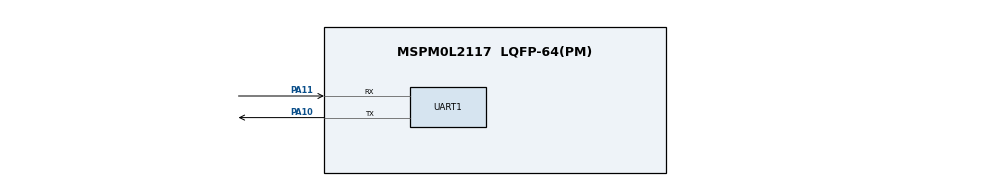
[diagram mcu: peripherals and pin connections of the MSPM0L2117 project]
//@cliArgs --device "MSPM0L211X" --package "LQFP-64(PM)" --part "Default"
//@v2CliArgs --device "MSPM0L2117" --package "LQFP-64(PM)"
// @cliArgs --board /ti/boards/LP_MSPM0L2117 --rtos nortos

/**
 * Import the modules used in this configuration.
 */
const UART   = scripting.addModule("/ti/driverlib/UART", {}, false);
const UART1  = UART.addInstance();

/**
 * Write custom configuration values to the imported modules.
 */

UART1.$name = "UART_0";
UART1.profile = "CONFIG_PROFILE_1";
UART1.targetBaudRate = 9600;
UART1.enableInternalLoopback = false;
UART1.enabledInterrupts = ["RX"];
UART1.rxFifoThreshold          = "DL_UART_RX_FIFO_LEVEL_ONE_ENTRY";
UART1.enableFIFO               = true;
UART1.peripheral.rxPin.$assign = "PA11";
UART1.peripheral.txPin.$assign = "PA10";

const SYSCTL = scripting.addModule("/ti/driverlib/SYSCTL");
SYSCTL.clockTreeEn = true;
SYSCTL.forceDefaultClkConfig = true;
